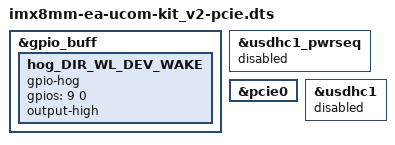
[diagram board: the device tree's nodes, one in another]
/*
 * Copyright 2019 Embedded Artists AB
 *
 * The code contained herein is licensed under the GNU General Public
 * License. You may obtain a copy of the GNU General Public License
 * Version 2 or later at the following locations:
 *
 * http://www.opensource.org/licenses/gpl-license.html
 * http://www.gnu.org/copyleft/gpl.html
 */

/dts-v1/;
 
#include "imx8mm-ea-ucom-kit_v2.dts"

&gpio_buff {
	hog_DIR_WL_DEV_WAKE {
		gpio-hog;
		gpios = <9 0>;
		/delete-property/ output-low;
		output-high;
	};
};

&usdhc1_pwrseq {
	status = "disabled";
};

&pcie0 {
	status = "okay";
};

&usdhc1 {
	status = "disabled";
};
